# ATmega3209 register map
Vendor: Atmel; File version: 1.0
CPU: other r0p0, little endian, no MPU, no FPU, 4 interrupt priority bits
Registers are 8-bit, read-write, reset 0x0 unless marked. A register's access mark holds for its fields unless they carry their own. Offsets are from the block's base; [hi:lo] are bit positions; {n}, {i} and the like mark numbered series; 'fields as' and 'values as' point back to an identical list.

## CPU
Base 0x00800034
0x00 CCP — Configuration Change Protection
  [7:0] CCP — CCP signature
    157=SPM (SPM Instruction Protection); 216=IOREG (IO Register Protection)
0x09 SPL — Stack Pointer Low
0x0A SPH — Stack Pointer High
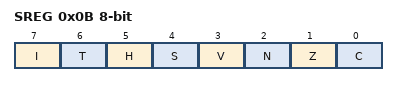
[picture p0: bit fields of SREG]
0x0B SREG — Status Register
  [7] I — Global Interrupt Enable Flag
  [6] T — Transfer Bit
  [5] H — Half Carry Flag
  [4] S — N Exclusive Or V Flag
  [3] V — Two's Complement Overflow Flag
  [2] N — Negative Flag
  [1] Z — Zero Flag
  [0] C — Carry Flag

## CPUINT — Interrupt Controller
Base 0x00800110
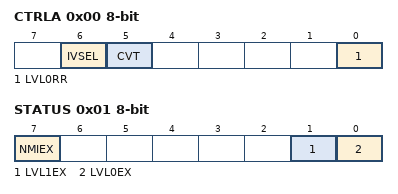
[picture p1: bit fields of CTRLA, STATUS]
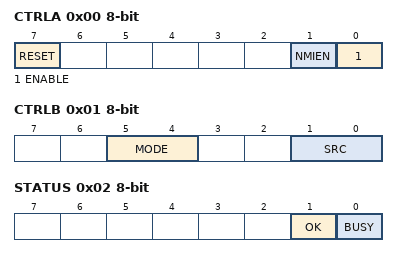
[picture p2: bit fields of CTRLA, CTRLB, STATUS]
0x00 CTRLA — Control A
  [6] IVSEL — Interrupt Vector Select
  [5] CVT — Compact Vector Table
  [0] LVL0RR — Round-robin Scheduling Enable
0x01 STATUS
  [7] NMIEX ro — Non-maskable Interrupt Executing
  [1] LVL1EX ro — Level 1 Interrupt Executing
  [0] LVL0EX ro — Level 0 Interrupt Executing
0x02 LVL0PRI — Interrupt Level 0 Priority
  [7:0] LVL0PRI — Interrupt Level Priority
0x03 LVL1VEC — Interrupt Level 1 Priority Vector
  [7:0] LVL1VEC — Interrupt Vector with High Priority

## CRCSCAN
Base 0x00800120
0x00 CTRLA — Control A
  [7] RESET — Reset CRC scan
  [1] NMIEN — Enable NMI Trigger
  [0] ENABLE — Enable CRC scan
0x01 CTRLB — Control B
  [5:4] MODE — CRC Flash Access Mode
    0=PRIORITY (Priority to flash)
  [1:0] SRC — CRC Source
    0=FLASH (CRC on entire flash); 1=APPLICATION (CRC on boot and appl section of flash); 2=BOOT (CRC on boot section of flash)
0x02 STATUS ro
  [1] OK — CRC Ok
  [0] BUSY — CRC Busy

## EVSYS — Event System
Base 0x00800180
0x00 STROBE wo — Channel Strobe
  [7:0] STROBE0 — Software event on channels
    1=EV_STROBE_CH0; 2=EV_STROBE_CH1; 4=EV_STROBE_CH2; 8=EV_STROBE_CH3; 16=EV_STROBE_CH4; 32=EV_STROBE_CH5; 64=EV_STROBE_CH6; 128=EV_STROBE_CH7
{0x10+i} CHANNEL{i} (i=0..7) — Multiplexer Channel {i}
  [7:0] GENERATOR — Generator selector
    0=OFF; 1=UPDI (Unified Program and Debug Interface); 6=RTC_OVF (Real Time Counter overflow); 7=RTC_CMP (Real Time Counter compare); {v}=RTC_PIT{v-8} (Periodic Interrupt Timer output {v-8}) (v=8..11); {v}=CCL_LUT{v-16} (Configurable Custom Logic LUT{v-16}) (v=16..19); 32=AC0_OUT (Analog Comparator 0 out); 36=ADC0_RESRDY (ADC 0 Result Ready Event); {v}=PORT0_PIN{v-64} (v=64..71); {v}=PORT1_PIN{v-72} (v=72..79); {v}=USART{v-96}_XCK (USART {v-96} Xclock) (v=96..99); 104=SPI0_SCK (SPI 0 Sclock); 128=TCA0_OVF_LUNF (Timer/Counter A0 overflow / low byte underflow); 129=TCA0_HUNF (Timer/Counter A0 high byte underflow (split mode)); 132=TCA0_CMP0 (Timer/Counter A0 compare 0); 133=TCA0_CMP1 (Timer/Counter A0 compare 1); 134=TCA0_CMP2 (Timer/Counter A0 compare 2); 160=TCB0_CAPT (Timer/Counter B0 capture); 162=TCB1_CAPT (Timer/Counter B1 capture); 164=TCB2_CAPT (Timer/Counter B2 capture); 166=TCB3_CAPT (Timer/Counter B3 capture)
{0x20+2i} USERCCLLUT{i}A (i=0..3) — User CCL LUT{i} Event A
  [7:0] CHANNEL — Channel selector
    0=OFF; {v}=Connect user to event channel {v-1} (v=1..8)
{0x21+2i} USERCCLLUT{i}B (i=0..3) — User CCL LUT{i} Event B
  fields as USERCCLLUT0A
0x28 USERADC0
  fields as USERCCLLUT0A
0x29 USEREVOUTA — User EVOUT Port A
  fields as USERCCLLUT0A
0x2A USEREVOUTB — User EVOUT Port B
  fields as USERCCLLUT0A
0x2B USEREVOUTC — User EVOUT Port C
  fields as USERCCLLUT0A
0x2C USEREVOUTD — User EVOUT Port D
  fields as USERCCLLUT0A
0x2D USEREVOUTE — User EVOUT Port E
  fields as USERCCLLUT0A
0x2E USEREVOUTF — User EVOUT Port F
  fields as USERCCLLUT0A
{0x2F+i} USERUSART{i} (i=0..3)
  fields as USERCCLLUT0A
0x33 USERTCA0
  fields as USERCCLLUT0A
{0x34+i} USERTCB{i} (i=0..3)
  fields as USERCCLLUT0A

## GPIO — General Purpose IO
Base 0x0080001C
{0x0+i} GPIOR{i} (i=0..3) — General Purpose IO Register {i}
